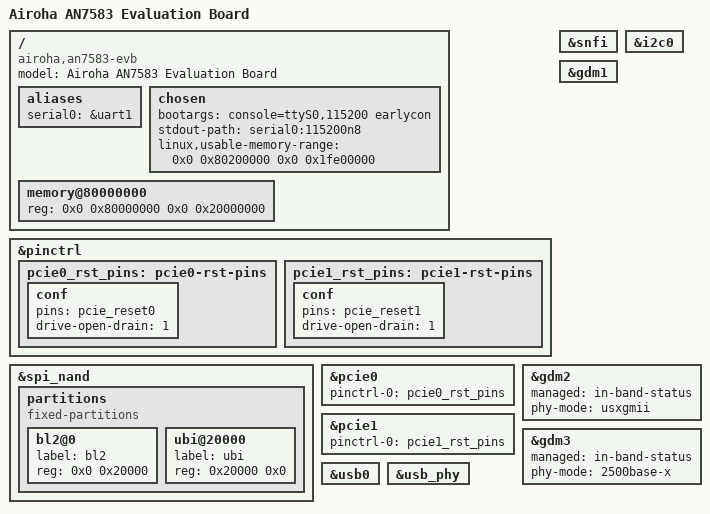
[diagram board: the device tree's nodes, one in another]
// SPDX-License-Identifier: (GPL-2.0-only OR BSD-2-Clause)
/dts-v1/;

#include <dt-bindings/leds/common.h>
#include <dt-bindings/gpio/gpio.h>
#include <dt-bindings/input/input.h>
#include "an7583.dtsi"

/ {
	model = "Airoha AN7583 Evaluation Board";
	compatible = "airoha,an7583-evb", "airoha,an7583", "airoha,en7583";

	aliases {
		serial0 = &uart1;
	};

	chosen {
		bootargs = "console=ttyS0,115200 earlycon";
		stdout-path = "serial0:115200n8";
		linux,usable-memory-range = <0x0 0x80200000 0x0 0x1fe00000>;
	};

	/* When running as a first-stage bootloader this isn't filled in automatically */
	memory@80000000 {
		device_type = "memory";
		reg = <0x0 0x80000000 0x0 0x20000000>;
	};
};

&pinctrl {
	pcie0_rst_pins: pcie0-rst-pins {
		conf {
			pins = "pcie_reset0";
			drive-open-drain = <1>;
		};
	};

	pcie1_rst_pins: pcie1-rst-pins {
		conf {
			pins = "pcie_reset1";
			drive-open-drain = <1>;
		};
	};
};

&snfi {
	status = "okay";
};

&spi_nand {
	partitions {
		compatible = "fixed-partitions";
		#address-cells = <1>;
		#size-cells = <1>;

		bl2@0 {
			label = "bl2";
			reg = <0x0 0x20000>;
		};

		ubi@20000 {
			label = "ubi";
			reg = <0x20000 0x0>;
		};
	};
};

&pcie0 {
	pinctrl-names = "default";
	pinctrl-0 = <&pcie0_rst_pins>;
	status = "okay";
};

&pcie1 {
	pinctrl-names = "default";
	pinctrl-0 = <&pcie1_rst_pins>;
	status = "okay";
};

&i2c0 {
	status = "okay";
};

&gdm1 {
	status = "okay";
};

&gdm2 {
	status = "okay";

	managed = "in-band-status";
	phy-mode = "usxgmii";
};

&gdm3 {
	status = "okay";

	managed = "in-band-status";
	phy-mode = "2500base-x";
};

/*
 * USB: the SoC default PHY list from an7583.dtsi is used, i.e. both USB 2.0
 * ports (phy@1fac0000 + 0x1000) and the USB 3.0 port (usb3-phy subnode, which
 * carries the SCU phandle used to switch the serdes shared with HSGMII to
 * USB). To keep the board USB 2.0 only, drop <&usb0_u3 PHY_TYPE_USB3> from
 * usb0's 'phys' and add "mediatek,u3p-dis-msk = <0x1>;".
 */
&usb0 {
	status = "okay";
};

&usb_phy {
	status = "okay";
};
